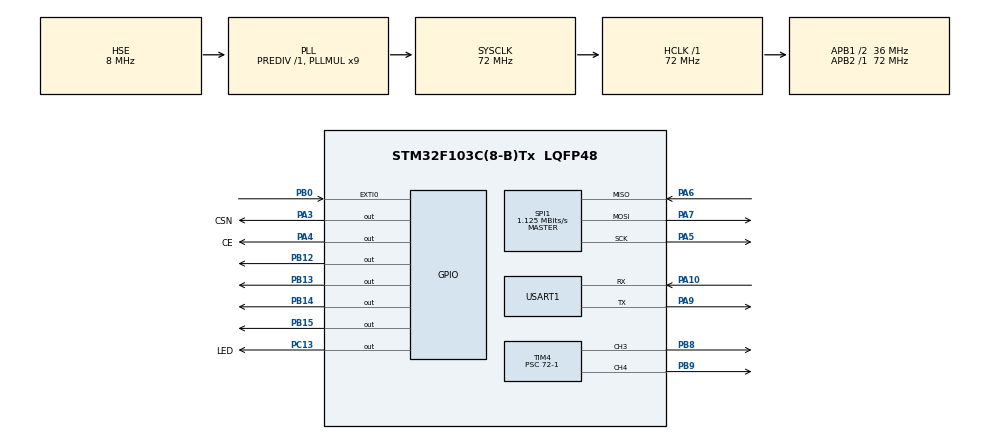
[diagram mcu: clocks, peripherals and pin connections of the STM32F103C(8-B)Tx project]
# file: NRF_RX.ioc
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Dma.Request0=USART1_RX
Dma.Request1=USART1_TX
Dma.USART1_RX.0.Direction=DMA_PERIPH_TO_MEMORY
Dma.USART1_RX.0.Instance=DMA1_Channel5
Dma.USART1_RX.0.MemDataAlignment=DMA_MDATAALIGN_BYTE
Dma.USART1_RX.0.MemInc=DMA_MINC_ENABLE
Dma.USART1_RX.0.Mode=DMA_NORMAL
Dma.USART1_RX.0.PeriphDataAlignment=DMA_PDATAALIGN_BYTE
Dma.USART1_RX.0.PeriphInc=DMA_PINC_DISABLE
Dma.USART1_RX.0.Priority=DMA_PRIORITY_LOW
Dma.USART1_TX.1.Direction=DMA_MEMORY_TO_PERIPH
Dma.USART1_TX.1.Instance=DMA1_Channel4
Dma.USART1_TX.1.MemDataAlignment=DMA_MDATAALIGN_BYTE
Dma.USART1_TX.1.MemInc=DMA_MINC_ENABLE
Dma.USART1_TX.1.Mode=DMA_NORMAL
Dma.USART1_TX.1.PeriphDataAlignment=DMA_PDATAALIGN_BYTE
Dma.USART1_TX.1.PeriphInc=DMA_PINC_DISABLE
Dma.USART1_TX.1.Priority=DMA_PRIORITY_LOW
Mcu.Family=STM32F1
Mcu.Name=STM32F103C(8-B)Tx
Mcu.Package=LQFP48
NVIC.DMA1_Channel4_IRQn=true\:0\:0\:false\:false\:true\:false\:true\:true
NVIC.DMA1_Channel5_IRQn=true\:0\:0\:false\:false\:true\:false\:true\:true
NVIC.EXTI0_IRQn=true\:0\:0\:false\:false\:true\:true\:true\:true
NVIC.PriorityGroup=NVIC_PRIORITYGROUP_4
PA10.Mode=Asynchronous
PA10.Signal=USART1_RX
PA13.Mode=Serial_Wire
PA13.Signal=SYS_JTMS-SWDIO
PA14.Mode=Serial_Wire
PA14.Signal=SYS_JTCK-SWCLK
PA3.GPIO_Label=CSN
PA3.Signal=GPIO_Output
PA4.GPIO_Label=CE
PA4.Signal=GPIO_Output
PA5.Mode=Full_Duplex_Master
PA5.Signal=SPI1_SCK
PA6.Mode=Full_Duplex_Master
PA6.Signal=SPI1_MISO
PA7.Mode=Full_Duplex_Master
PA7.Signal=SPI1_MOSI
PA9.Mode=Asynchronous
PA9.Signal=USART1_TX
PB0.GPIO_ModeDefaultEXTI=GPIO_MODE_IT_FALLING
PB0.GPIO_PuPd=GPIO_PULLUP
PB0.Signal=GPXTI0
PB12.Signal=GPIO_Output
PB13.Signal=GPIO_Output
PB14.Signal=GPIO_Output
PB15.Signal=GPIO_Output
PB8.Signal=S_TIM4_CH3
PB9.Signal=S_TIM4_CH4
PC13-TAMPER-RTC.GPIO_Label=LED
PC13-TAMPER-RTC.Signal=GPIO_Output
PC14-OSC32_IN.Mode=LSE-External-Oscillator
PC14-OSC32_IN.Signal=RCC_OSC32_IN
PC15-OSC32_OUT.Mode=LSE-External-Oscillator
PC15-OSC32_OUT.Signal=RCC_OSC32_OUT
PD0-OSC_IN.Mode=HSE-External-Oscillator
PD0-OSC_IN.Signal=RCC_OSC_IN
PD1-OSC_OUT.Mode=HSE-External-Oscillator
PD1-OSC_OUT.Signal=RCC_OSC_OUT
ProjectManager.HeapSize=0x200
ProjectManager.StackSize=0x400
ProjectManager.TargetToolchain=MDK-ARM V5.32
RCC.AHBFreq_Value=72000000
RCC.APB1CLKDivider=RCC_HCLK_DIV2
RCC.APB1Freq_Value=36000000
RCC.APB1TimFreq_Value=72000000
RCC.APB2Freq_Value=72000000
RCC.APB2TimFreq_Value=72000000
RCC.HCLKFreq_Value=72000000
RCC.PLLMUL=RCC_PLL_MUL9
RCC.PLLSourceVirtual=RCC_PLLSOURCE_HSE
RCC.SYSCLKFreq_VALUE=72000000
RCC.SYSCLKSource=RCC_SYSCLKSOURCE_PLLCLK
RCC.USBFreq_Value=72000000
SH.S_TIM4_CH3.0=TIM4_CH3,PWM Generation3 CH3
SH.S_TIM4_CH4.0=TIM4_CH4,PWM Generation4 CH4
SPI1.BaudRatePrescaler=SPI_BAUDRATEPRESCALER_64
SPI1.CalculateBaudRate=1.125 MBits/s
SPI1.Direction=SPI_DIRECTION_2LINES
SPI1.Mode=SPI_MODE_MASTER
SPI1.VirtualType=VM_MASTER
TIM4.Channel-PWM\ Generation3\ CH3=TIM_CHANNEL_3
TIM4.Channel-PWM\ Generation4\ CH4=TIM_CHANNEL_4
TIM4.Period=1000-1
TIM4.Prescaler=72-1
USART1.VirtualMode=VM_ASYNC
board=custom

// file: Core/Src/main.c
/* USER CODE BEGIN Header */
/**
  ******************************************************************************
  * @file           : main.c
  * @brief          : Main program body
  ******************************************************************************
  * @attention
  *
  * Copyright (c) 2026 STMicroelectronics.
  * All rights reserved.
  *
  * This software is licensed under terms that can be found in the LICENSE file
  * in the root directory of this software component.
  * If no LICENSE file comes with this software, it is provided AS-IS.
  *
  ******************************************************************************
  */
/* USER CODE END Header */
#include "main.h"
#include "dma.h"
#include "spi.h"
#include "tim.h"
#include "usart.h"
#include "gpio.h"

/* USER CODE BEGIN Includes */
#include <stdbool.h>

#include "serial.h"
#include "nrf24l01.h"

/* USER CODE END Includes */

void SystemClock_Config(void);

int main(void)
{

  /* MCU Configuration--------------------------------------------------------*/

  /* Reset of all peripherals, Initializes the Flash interface and the Systick. */
  HAL_Init();

  /* Configure the system clock */
  SystemClock_Config();

  /* Initialize all configured peripherals */
  MX_GPIO_Init();
  MX_DMA_Init();
  MX_TIM4_Init();
  MX_SPI1_Init();
  MX_USART1_UART_Init();
  /* USER CODE BEGIN 2 */

const uint8_t NRF24_ADDR[5] = {0x11,0x22,0x33,0x44,0x55};
uint8_t nrf_rx_buf[32]={0};

if(NRF24_Init(NRF24_MODE_RX, NRF24_ADDR) != 0){
printf("NRF24L01 Init Failed!\r\n");
while(1);
}else{
printf("NRF24L01 Init SUCCESS.\r\n");
}

  /* USER CODE END 2 */

  /* Infinite loop */
  /* USER CODE BEGIN WHILE */
  while (1)
  {
uint8_t rx_state = NRF24_RxPacket(nrf_rx_buf);
if(rx_state == 0){
  printf("NRF24_RX.data:%s \r\n", nrf_rx_buf);
  //sscnaf((char*)nrf_rx_buf, "weight:%f", &weight) == 1

  memset(nrf_rx_buf,0,32);
}

    /* USER CODE END WHILE */

  }
}

void SystemClock_Config(void)
{
  RCC_OscInitTypeDef RCC_OscInitStruct = {0};
  RCC_ClkInitTypeDef RCC_ClkInitStruct = {0};

  /** Initializes the RCC Oscillators according to the specified parameters
  * in the RCC_OscInitTypeDef structure.
  */
  RCC_OscInitStruct.OscillatorType = RCC_OSCILLATORTYPE_HSE;
  RCC_OscInitStruct.HSEState = RCC_HSE_ON;
  RCC_OscInitStruct.HSEPredivValue = RCC_HSE_PREDIV_DIV1;
  RCC_OscInitStruct.HSIState = RCC_HSI_ON;
  RCC_OscInitStruct.PLL.PLLState = RCC_PLL_ON;
  RCC_OscInitStruct.PLL.PLLSource = RCC_PLLSOURCE_HSE;
  RCC_OscInitStruct.PLL.PLLMUL = RCC_PLL_MUL9;
  if (HAL_RCC_OscConfig(&RCC_OscInitStruct) != HAL_OK)
  {
    Error_Handler();
  }

  /** Initializes the CPU, AHB and APB buses clocks
  */
  RCC_ClkInitStruct.ClockType = RCC_CLOCKTYPE_HCLK|RCC_CLOCKTYPE_SYSCLK
                              |RCC_CLOCKTYPE_PCLK1|RCC_CLOCKTYPE_PCLK2;
  RCC_ClkInitStruct.SYSCLKSource = RCC_SYSCLKSOURCE_PLLCLK;
  RCC_ClkInitStruct.AHBCLKDivider = RCC_SYSCLK_DIV1;
  RCC_ClkInitStruct.APB1CLKDivider = RCC_HCLK_DIV2;
  RCC_ClkInitStruct.APB2CLKDivider = RCC_HCLK_DIV1;

  if (HAL_RCC_ClockConfig(&RCC_ClkInitStruct, FLASH_LATENCY_2) != HAL_OK)
  {
    Error_Handler();
  }
}

void Error_Handler(void)
{
  __disable_irq();
  while (1)
  {
  }
}
